# STM32F41x register map
File version: 1.5
Registers are 32-bit, read-write, reset 0x0 unless marked. A register's access mark holds for its fields unless they carry their own. Offsets are from the block's base; [hi:lo] are bit positions; {n}, {i} and the like mark numbered series; 'fields as' and 'values as' point back to an identical list.

## FSMC — Flexible static memory controller
Base 0xA0000000
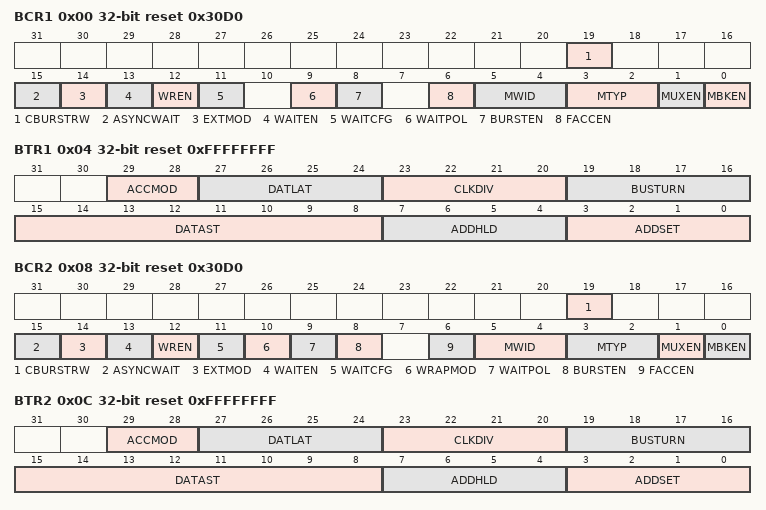
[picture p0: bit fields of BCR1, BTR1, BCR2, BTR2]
0x00 BCR1 reset 0x30D0 — SRAM/NOR-Flash chip-select control register 1
  [19] CBURSTRW, [15] ASYNCWAIT, [14] EXTMOD, [13] WAITEN, [12] WREN, [11] WAITCFG, [9] WAITPOL, [8] BURSTEN, [6] FACCEN, [5:4] MWID, [3:2] MTYP, [1] MUXEN, [0] MBKEN
0x04 BTR1 reset 0xFFFFFFFF — SRAM/NOR-Flash chip-select timing register 1
  [29:28] ACCMOD, [27:24] DATLAT, [23:20] CLKDIV, [19:16] BUSTURN, [15:8] DATAST, [7:4] ADDHLD, [3:0] ADDSET
0x08 BCR2 reset 0x30D0 — SRAM/NOR-Flash chip-select control register 2
  [19] CBURSTRW, [15] ASYNCWAIT, [14] EXTMOD, [13] WAITEN, [12] WREN, [11] WAITCFG, [10] WRAPMOD, [9] WAITPOL, [8] BURSTEN, [6] FACCEN, [5:4] MWID, [3:2] MTYP, [1] MUXEN, [0] MBKEN
0x0C BTR2 reset 0xFFFFFFFF — SRAM/NOR-Flash chip-select timing register 2
  fields as BTR1
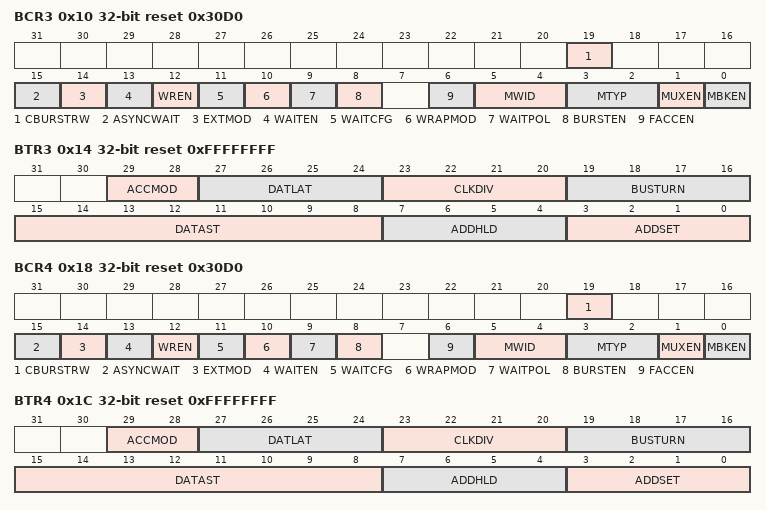
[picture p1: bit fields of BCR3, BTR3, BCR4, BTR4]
0x10 BCR3 reset 0x30D0 — SRAM/NOR-Flash chip-select control register 3
  fields as BCR2
0x14 BTR3 reset 0xFFFFFFFF — SRAM/NOR-Flash chip-select timing register 3
  fields as BTR1
0x18 BCR4 reset 0x30D0 — SRAM/NOR-Flash chip-select control register 4
  fields as BCR2
0x1C BTR4 reset 0xFFFFFFFF — SRAM/NOR-Flash chip-select timing register 4
  fields as BTR1
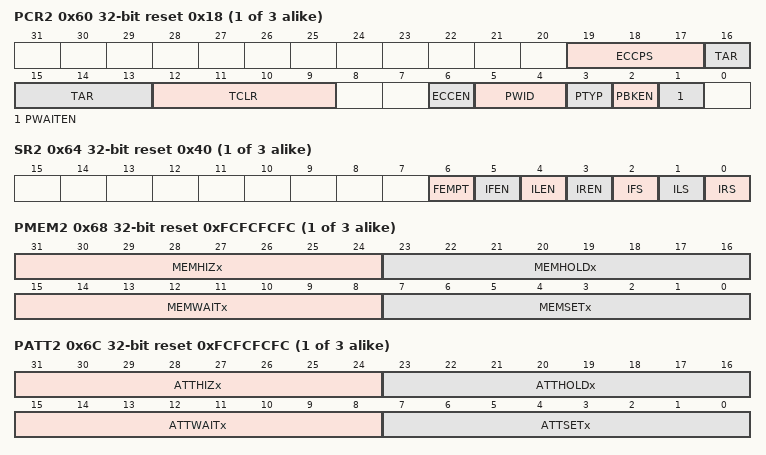
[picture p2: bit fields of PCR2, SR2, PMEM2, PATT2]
{0x20+0x20*i} PCR{i} reset 0x18 (i=2..4) — PC Card/NAND Flash control register {i}
  [19:17] ECCPS, [16:13] TAR, [12:9] TCLR, [6] ECCEN, [5:4] PWID, [3] PTYP, [2] PBKEN, [1] PWAITEN
{0x24+0x20*i} SR{i} access per field reset 0x40 (i=2..4) — FIFO status and interrupt register {i}
  [6] FEMPT ro, [5] IFEN rw, [4] ILEN rw, [3] IREN rw, [2] IFS rw, [1] ILS rw, [0] IRS rw
{0x28+0x20*i} PMEM{i} reset 0xFCFCFCFC (i=2..4) — Common memory space timing register {i}
  [31:24] MEMHIZx, [23:16] MEMHOLDx, [15:8] MEMWAITx, [7:0] MEMSETx
{0x2C+0x20*i} PATT{i} reset 0xFCFCFCFC (i=2..4) — Attribute memory space timing register {i}
  [31:24] ATTHIZx, [23:16] ATTHOLDx, [15:8] ATTWAITx, [7:0] ATTSETx
0x74 ECCR2 ro — ECC result register 2
  [31:0] ECCx
0x94 ECCR3 ro — ECC result register 3
  [31:0] ECCx
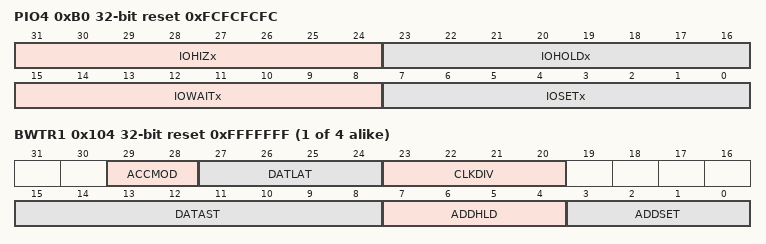
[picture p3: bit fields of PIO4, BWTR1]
0xB0 PIO4 reset 0xFCFCFCFC — I/O space timing register 4
  [31:24] IOHIZx, [23:16] IOHOLDx, [15:8] IOWAITx, [7:0] IOSETx
{0xFC+8i} BWTR{i} reset 0xFFFFFFF (i=1..4) — SRAM/NOR-Flash write timing registers {i}
  [29:28] ACCMOD, [27:24] DATLAT, [23:20] CLKDIV, [15:8] DATAST, [7:4] ADDHLD, [3:0] ADDSET

## DBG — Debug support
Base 0xE0042000
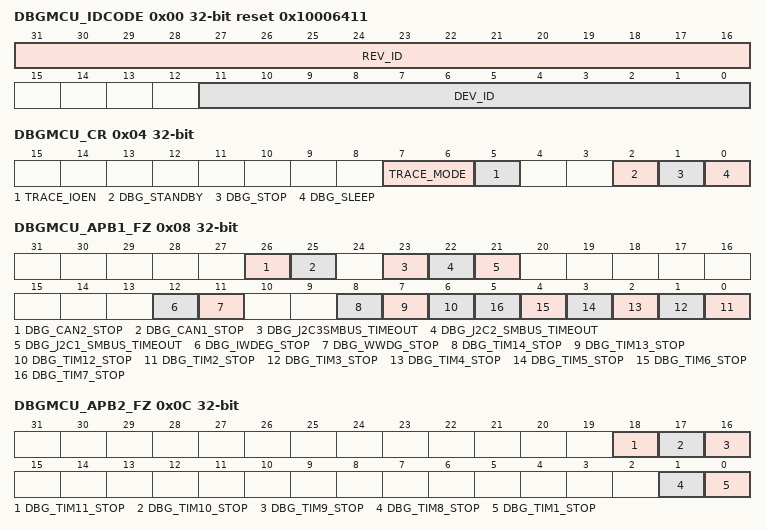
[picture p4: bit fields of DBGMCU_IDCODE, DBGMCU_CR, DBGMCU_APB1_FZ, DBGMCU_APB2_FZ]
0x00 DBGMCU_IDCODE ro reset 0x10006411 — IDCODE
  [31:16] REV_ID, [11:0] DEV_ID
0x04 DBGMCU_CR — Control Register
  [7:6] TRACE_MODE, [5] TRACE_IOEN, [2] DBG_STANDBY, [1] DBG_STOP, [0] DBG_SLEEP
0x08 DBGMCU_APB1_FZ — Debug MCU APB1 Freeze registe
  [26] DBG_CAN2_STOP, [25] DBG_CAN1_STOP, [23] DBG_J2C3SMBUS_TIMEOUT, [22] DBG_J2C2_SMBUS_TIMEOUT, [21] DBG_J2C1_SMBUS_TIMEOUT, [12] DBG_IWDEG_STOP, [11] DBG_WWDG_STOP, [8] DBG_TIM14_STOP, [7] DBG_TIM13_STOP, [6] DBG_TIM12_STOP, [n-2] DBG_TIM{n}_STOP (n=2..7)
0x0C DBGMCU_APB2_FZ — Debug MCU APB2 Freeze registe
  [18] DBG_TIM11_STOP — TIM11 counter stopped when core is halted
  [17] DBG_TIM10_STOP — TIM10 counter stopped when core is halted
  [16] DBG_TIM9_STOP — TIM9 counter stopped when core is halted
  [1] DBG_TIM8_STOP — TIM8 counter stopped when core is halted
  [0] DBG_TIM1_STOP — TIM1 counter stopped when core is halted

## GPIOI — General-purpose I/Os
Base 0x40022000
Same registers: GPIOC 0x40020800, GPIOD 0x40020C00, GPIOE 0x40021000, GPIOF 0x40021400, GPIOG 0x40021800, GPIOH 0x40021C00
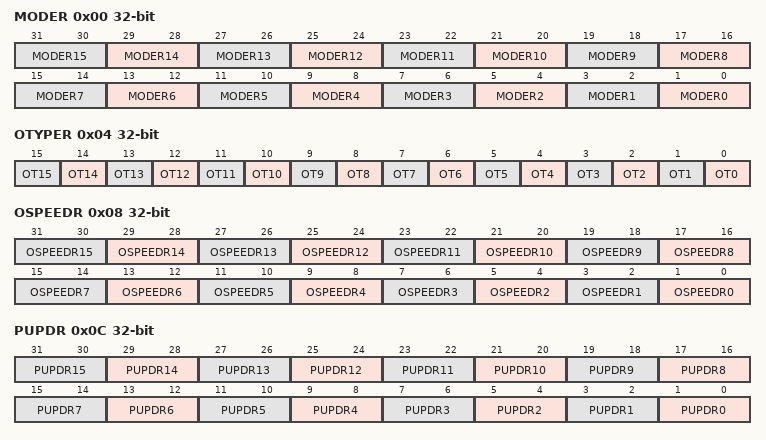
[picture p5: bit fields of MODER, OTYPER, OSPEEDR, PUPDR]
0x00 MODER — GPIO port flightMode register
  [2n+1:2n] MODER{n} (n=0..15) — Port x configuration bits (y = 0..15)
0x04 OTYPER — GPIO port output type register
  [n] OT{n} (n=0..15) — Port x configuration bits (y = 0..15)
0x08 OSPEEDR — GPIO port output speed register
  [2n+1:2n] OSPEEDR{n} (n=0..15) — Port x configuration bits (y = 0..15)
0x0C PUPDR — GPIO port pull-up/pull-down register
  [2n+1:2n] PUPDR{n} (n=0..15) — Port x configuration bits (y = 0..15)
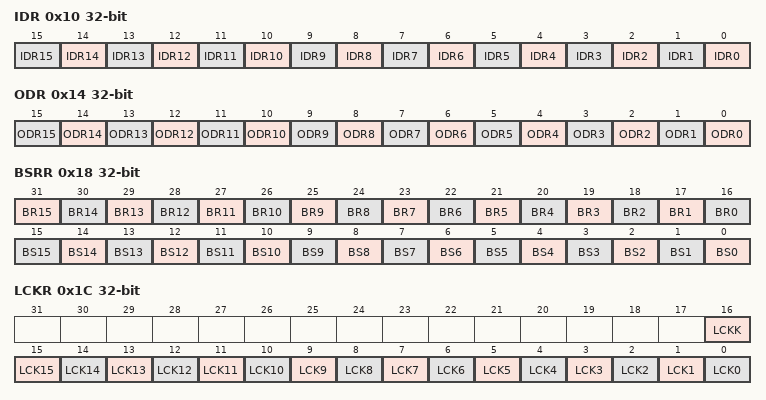
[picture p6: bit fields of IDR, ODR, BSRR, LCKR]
0x10 IDR ro — GPIO port input data register
  [n] IDR{n} (n=0..15) — Port input data (y = 0..15)
0x14 ODR — GPIO port output data register
  [n] ODR{n} (n=0..15) — Port output data (y = 0..15)
0x18 BSRR wo — GPIO port bit set/reset register
  [n+16] BR{n} (n=1..15) — Port x reset bit y (y = 0..15)
  [16] BR0 — Port x set bit y (y= 0..15)
  [n] BS{n} (n=0..15) — Port x set bit y (y= 0..15)
0x1C LCKR — GPIO port configuration lock register
  [16] LCKK — Port x lock bit y (y= 0..15)
  [n] LCK{n} (n=0..15) — Port x lock bit y (y= 0..15)
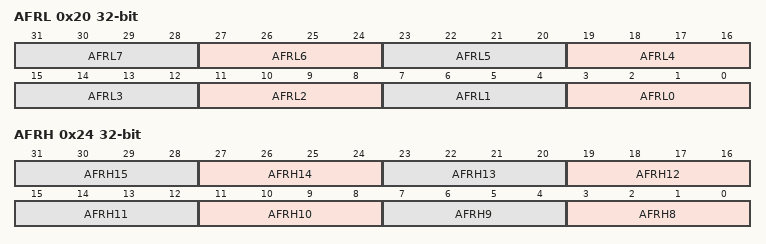
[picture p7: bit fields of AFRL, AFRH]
0x20 AFRL — GPIO alternate function low register
  [4n+3:4n] AFRL{n} (n=0..7) — Alternate function selection for port x bit y (y = 0..7)
0x24 AFRH — GPIO alternate function high register
  [4n-29:4n-32] AFRH{n} (n=8..15) — Alternate function selection for port x bit y (y = 8..15)

## GPIOB — General-purpose I/Os
Base 0x40020400
Registers as GPIOI; these are added or differ:
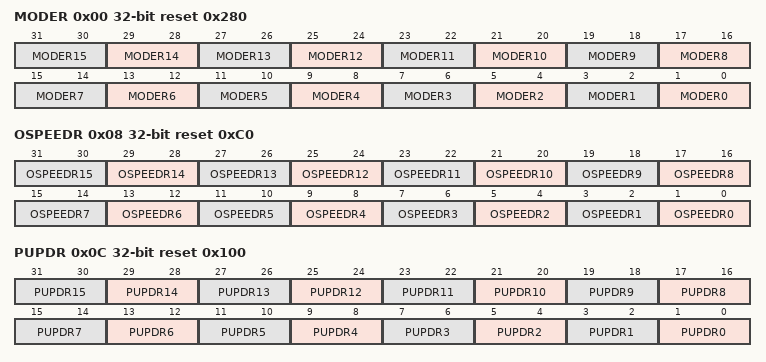
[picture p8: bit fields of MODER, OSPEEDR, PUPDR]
0x00 MODER reset 0x280 — GPIO port flightMode register
  [2n+1:2n] MODER{n} (n=0..15) — Port x configuration bits (y = 0..15)
0x08 OSPEEDR reset 0xC0 — GPIO port output speed register
  [2n+1:2n] OSPEEDR{n} (n=0..15) — Port x configuration bits (y = 0..15)
0x0C PUPDR reset 0x100 — GPIO port pull-up/pull-down register
  [2n+1:2n] PUPDR{n} (n=0..15) — Port x configuration bits (y = 0..15)

## GPIOA — General-purpose I/Os
Base 0x40020000
Registers as GPIOI; these are added or differ:
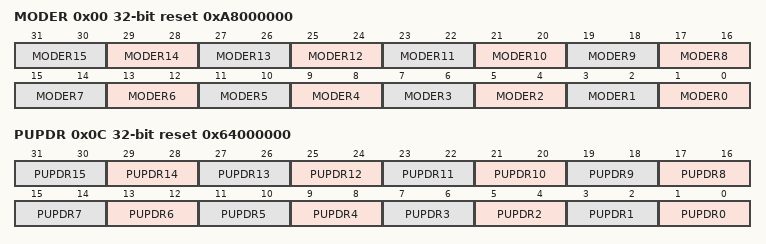
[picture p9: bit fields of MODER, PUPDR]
0x00 MODER reset 0xA8000000 — GPIO port flightMode register
  [2n+1:2n] MODER{n} (n=0..15) — Port x configuration bits (y = 0..15)
0x0C PUPDR reset 0x64000000 — GPIO port pull-up/pull-down register
  [2n+1:2n] PUPDR{n} (n=0..15) — Port x configuration bits (y = 0..15)
